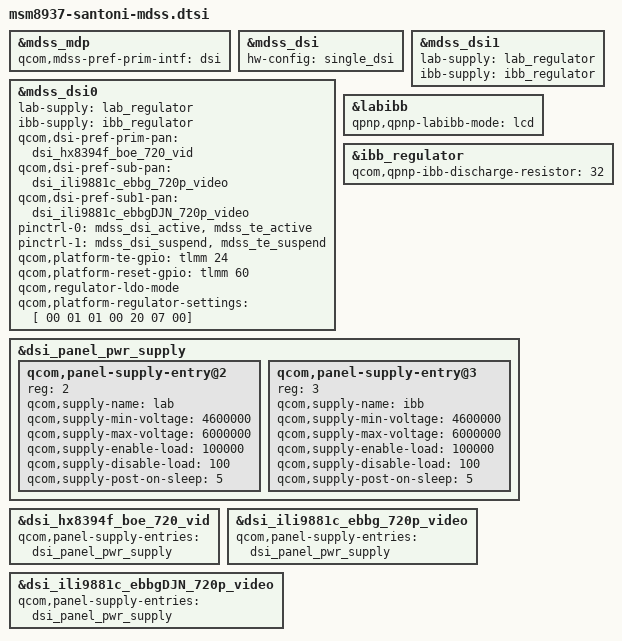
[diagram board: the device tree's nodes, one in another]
#include "dsi-panel-hx8394f-boe-720p-video.dtsi"
#include "dsi-panel-ili9881c-ebbg-720p-video.dtsi"
#include "dsi-panel-ili9881c-ebbgDJN-720p-video.dtsi"

&mdss_mdp {
	qcom,mdss-pref-prim-intf = "dsi";
};

&mdss_dsi {
	hw-config = "single_dsi";
};

&mdss_dsi0 {
	lab-supply = <&lab_regulator>;
	ibb-supply = <&ibb_regulator>;

	qcom,dsi-pref-prim-pan = <&dsi_hx8394f_boe_720_vid>;
	qcom,dsi-pref-sub-pan = <&dsi_ili9881c_ebbg_720p_video>;
	qcom,dsi-pref-sub1-pan = <&dsi_ili9881c_ebbgDJN_720p_video>;
	pinctrl-names = "mdss_default", "mdss_sleep";
	pinctrl-0 = <&mdss_dsi_active &mdss_te_active>;
	pinctrl-1 = <&mdss_dsi_suspend &mdss_te_suspend>;

	qcom,platform-te-gpio = <&tlmm 24 0>;
	qcom,platform-reset-gpio = <&tlmm 60 0>;

	qcom,regulator-ldo-mode;
	qcom,platform-regulator-settings = [ 00 01 01 00 20 07 00];

};

&mdss_dsi1 {
	lab-supply = <&lab_regulator>;
	ibb-supply = <&ibb_regulator>;
};

&labibb {
	status = "ok";
	qpnp,qpnp-labibb-mode = "lcd";
};

&ibb_regulator {
	qcom,qpnp-ibb-discharge-resistor = <32>;
};

&dsi_panel_pwr_supply {
	qcom,panel-supply-entry@2 {
		reg = <2>;
		qcom,supply-name = "lab";
		qcom,supply-min-voltage = <4600000>;
		qcom,supply-max-voltage = <6000000>;
		qcom,supply-enable-load = <100000>;
		qcom,supply-disable-load = <100>;
		qcom,supply-post-on-sleep = <5>;
	};

	qcom,panel-supply-entry@3 {
		reg = <3>;
		qcom,supply-name = "ibb";
		qcom,supply-min-voltage = <4600000>;
		qcom,supply-max-voltage = <6000000>;
		qcom,supply-enable-load = <100000>;
		qcom,supply-disable-load = <100>;
		qcom,supply-post-on-sleep = <5>;
	};
};

&dsi_hx8394f_boe_720_vid {
	qcom,panel-supply-entries = <&dsi_panel_pwr_supply>;
};

&dsi_ili9881c_ebbg_720p_video {
	qcom,panel-supply-entries = <&dsi_panel_pwr_supply>;
};

&dsi_ili9881c_ebbgDJN_720p_video {
	qcom,panel-supply-entries = <&dsi_panel_pwr_supply>;
};
